# Template register map
Vendor: VendorName Co.Ltd; Series: SeriesName; File version: 1.2
CPU: CM7 r0p1, little endian, MPU, FPU, 4 interrupt priority bits
Registers are 32-bit, read-write, no defined reset value unless marked. A register's access mark holds for its fields unless they carry their own. Offsets are from the block's base; [hi:lo] are bit positions; {n}, {i} and the like mark numbered series.

## TRNG — True Random Number Generator
Base 0x40082000
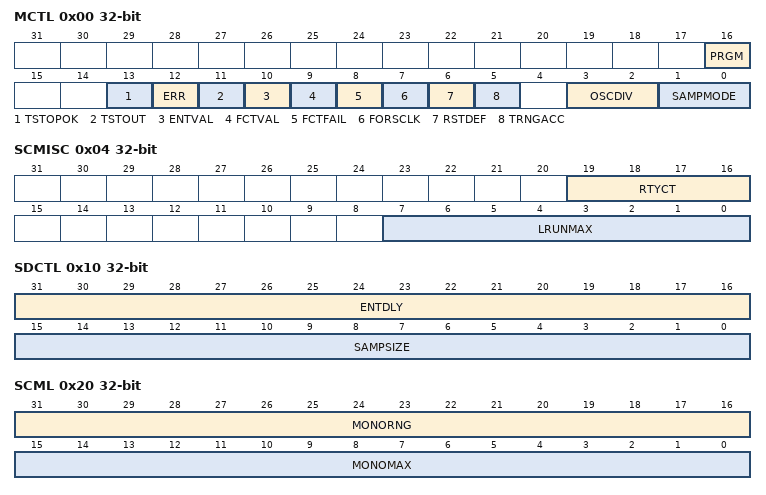
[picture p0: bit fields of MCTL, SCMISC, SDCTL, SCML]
0x00 MCTL — TRNG miscellaneous control register
  [16] PRGM — TRNG PRGM bit: programming mode select
  [13] TSTOPOK ro — TRNG TSTOPOK bit: TRNG module status
  [12] ERR — TRNG ERR bit: error status
  [11] TSTOUT ro — TRNG TSTOUT bit: test points within the ring oscillator
  [10] ENTVAL ro — TRNG ENTVAL bit: whether random number valid
  [9] FCTVAL ro — TRNG FCTVAL bit: whether frequency counting valid
  [8] FCTFAIL ro — TRNG FCTFAIL bit: counting frequency is normal or failure
  [7] FORSCLK — TRNG FORSCLK bit: force system clock
  [6] RSTDEF wo — TRNG RSTDEF bit: reset default
  [5] TRNGACC — TRNG TRNGACC bit: TRNG access mode
  [3:2] OSCDIV — TRNG OSCDIV[1:0] bit: oscillator divide
  [1:0] SAMPMODE — TRNG SAMPMODE[1:0] bit: sample mode
0x04 SCMISC — TRNG statistical check miscellaneous register
  [19:16] RTYCT — TRNG RTYCT[3:0] bit: retry count
  [7:0] LRUNMAX — TRNG LRUNMAX[7:0] bit: long run max limit
0x08 PKRRNG — TRNG poker range register
  [15:0] PKRRNG — TRNG PKRRNG[15:0] bit: poker range
0x0C PKRMAX — TRNG poker maximum limit register
  [23:0] PKRMAX — TRNG PKRMAX[23:0] bit: poker maximum limit
0x0C PKRSQ ro (alternate view of PKRMAX) — TRNG poker square calculation result register
  [23:0] PKRSQ — TRNG PKRSQ[23:0] bit: poker square calculation result
0x10 SDCTL — TRNG poker square calculation result register
  [31:16] ENTDLY — TRNG ENTDLY[15:0] bit: entropy delay
  [15:0] SAMPSIZE — TRNG SAMPSIZE[15:0] bit: sample size
0x14 SBLIM — TRNG sparse bit limit register
  [9:0] SBLIM — TRNG SBLIM[9:0] bit: sparse bit limit
0x14 TOTSAM ro (alternate view of SBLIM) — TRNG total samples register
  [19:0] TOTSAM — TRNG TOTSAM[19:0] bit: total sample
0x18 FRQMIN — TRNG frequency count minimum limit register
  [21:0] FRQMIN — TRNG FRQMIN[21:0] bit: frequency count minimum limit
0x1C FRQCNT ro — TRNG frequency count register
  [21:0] FRQCT — TRNG FRQCT[21:0] bit: frequency count
0x1C FRQMAX (alternate view of FRQCNT) — TRNG frequency count maximum limit register
  [21:0] FRQMAX — TRNG FRQMAX[21:0] bit: frequency counter maximum limit
0x20 SCMC ro — TRNG statistical check monobit count register
  [15:0] MONOCT — TRNG MONOCT[15:0] bit: monobit count
0x20 SCML (alternate view of SCMC) — TRNG statistical check monobit limit register
  [31:16] MONORNG — TRNG MONORNG[15:0] bit: monobit count
  [15:0] MONOMAX — TRNG MONOMAX[15:0] bit: monobit maximum limit
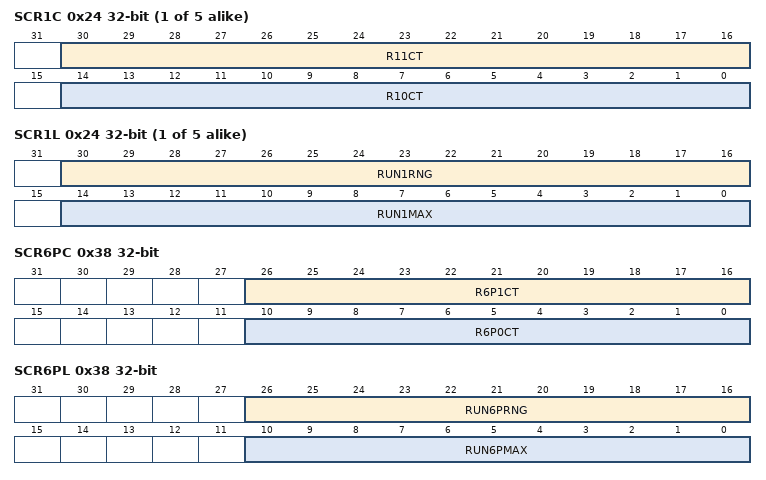
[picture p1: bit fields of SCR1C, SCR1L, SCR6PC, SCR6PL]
{0x20+4i} SCR{i}C ro (i=1..5) — TRNG statistical check run length {i} count register
  [{31-i}:16] R{10i+1}CT — TRNG R{10i+1}CT[{15-i}:0] bit: runs of one length {i} count
  [{15-i}:0] R{10i}CT — TRNG R{10i}CT[{15-i}:0] bit: runs of zero length {i} count
{0x20+4i} SCR{i}L (alternate view of SCR{i}C) (i=1..5) — TRNG statistical check run length {i} limit register
  [{31-i}:16] RUN{i}RNG — TRNG RUN{i}RNG[{15-i}:0] bit: run length {i} range
  [{15-i}:0] RUN{i}MAX — TRNG RUN{i}MAX[{15-i}:0] bit: run length {i} maximum limit
0x38 SCR6PC ro — TRNG statistical check run length 6 count register
  [26:16] R6P1CT — TRNG R6P1CT[10:0] bit: runs of one length 6 count
  [10:0] R6P0CT — TRNG R6P0CT[10:0] bit: runs of zero length 6 count
0x38 SCR6PL (alternate view of SCR6PC) — TRNG statistical check run length 6 limit register
  [26:16] RUN6PRNG — TRNG RUN6PRNG[10:0] bit: run length 6 range
  [10:0] RUN6PMAX — TRNG RUN6PMAX[10:0] bit: run length 6 maximum limit
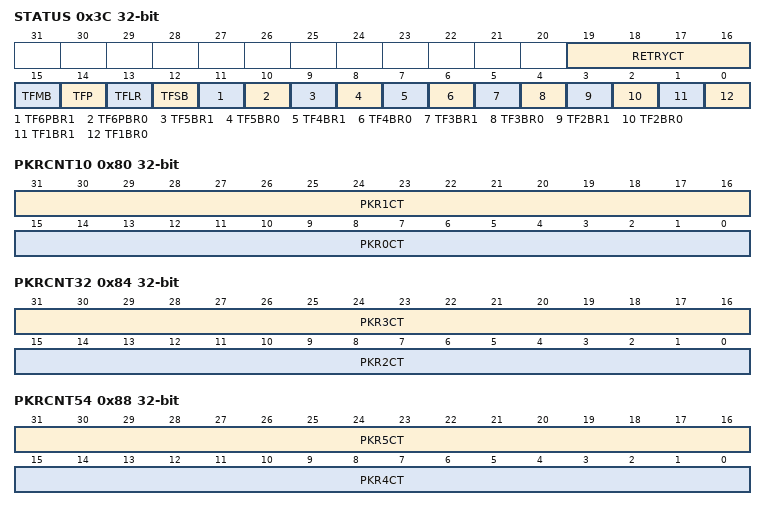
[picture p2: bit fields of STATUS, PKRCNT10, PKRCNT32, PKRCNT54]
0x3C STATUS ro — TRNG status register
  [19:16] RETRYCT — TRNG RETRYCT[3:0] bit: retry count
  [15] TFMB — TRNG TFMB bit: single bit testing result
  [14] TFP — TRNG TFP bit: poker testing result
  [13] TFLR — TRNG TFLR bit: long sequence testing result
  [12] TFSB — TRNG TFSB bit: sparse bits testing result
  [11] TF6PBR1 — TRNG TF6PBR1 bit: more than six consecutive ones testing result
  [10] TF6PBR0 — TRNG TF6PBR0 bit: more than six consecutive zeros testing result
  [9] TF5BR1 — TRNG TF5BR1 bit: five consecutive ones testing result
  [8] TF5BR0 — TRNG TF5BR0 bit: five consecutive zeros testing result
  [7] TF4BR1 — TRNG TF4BR1 bit: four consecutive ones testing result
  [6] TF4BR0 — TRNG TF4BR0 bit: four consecutive zeros testing result
  [5] TF3BR1 — TRNG TF3BR1 bit: three consecutive ones testing result
  [4] TF3BR0 — TRNG TF3BR0 bit: three consecutive zeros testing result
  [3] TF2BR1 — TRNG TF2BR1 bit: two consecutive ones testing result
  [2] TF2BR0 — TRNG TF2BR0 bit: two consecutive zeros testing result
  [1] TF1BR1 — TRNG TF1BR1 bit: one consecutive one testing result
  [0] TF1BR0 — TRNG TF1BR0 bit: one consecutive zero testing result
{0x40+4i} ENTX[{i}] (i=0..15) ro — Grouping of ENT0~ENT15
  [31:0] ENT — TRNG ENT[31:0] bit: entropy value
0x80 PKRCNT10 ro — TRNG statistical check poker count 1 and 0 register
  [31:16] PKR1CT — TRNG PKR1CT[15:0] bit: poker 1h count
  [15:0] PKR0CT — TRNG PKR0CT[15:0] bit: poker 0h count
0x84 PKRCNT32 ro — TRNG statistical check poker count 3 and 2 register
  [31:16] PKR3CT — TRNG PKR3CT[15:0] bit: poker 3h count
  [15:0] PKR2CT — TRNG PKR2CT[15:0] bit: poker 2h count
0x88 PKRCNT54 ro — TRNG statistical check poker count 5 and 4 register
  [31:16] PKR5CT — TRNG PKR5CT[15:0] bit: poker 5h count
  [15:0] PKR4CT — TRNG PKR4CT[15:0] bit: poker 4h count
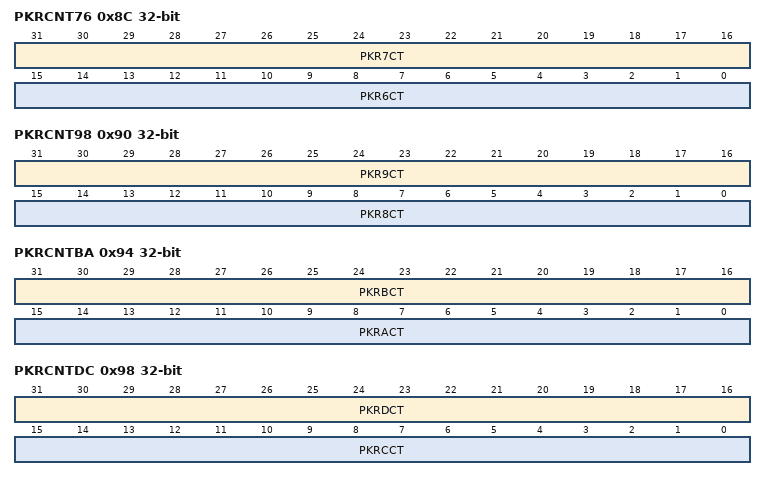
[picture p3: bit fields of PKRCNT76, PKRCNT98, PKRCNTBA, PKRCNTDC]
0x8C PKRCNT76 ro — TRNG statistical check poker count 7 and 6 register
  [31:16] PKR7CT — TRNG PKR7CT[15:0] bit: poker 7h count
  [15:0] PKR6CT — TRNG PKR6CT[15:0] bit: poker 6h count
0x90 PKRCNT98 ro — TRNG statistical check poker count 9 and 8 register
  [31:16] PKR9CT — TRNG PKR9CT[15:0] bit: poker 9h count
  [15:0] PKR8CT — TRNG PKR8CT[15:0] bit: poker 8h count
0x94 PKRCNTBA ro — TRNG statistical check poker count B and A register
  [31:16] PKRBCT — TRNG PKRBCT[15:0] bit: poker Bh count
  [15:0] PKRACT — TRNG PKRACT[15:0] bit: poker Ah count
0x98 PKRCNTDC ro — TRNG statistical check poker count D and C register
  [31:16] PKRDCT — TRNG PKRDCT[15:0] bit: poker Dh count
  [15:0] PKRCCT — TRNG PKRCCT[15:0] bit: poker Ch count
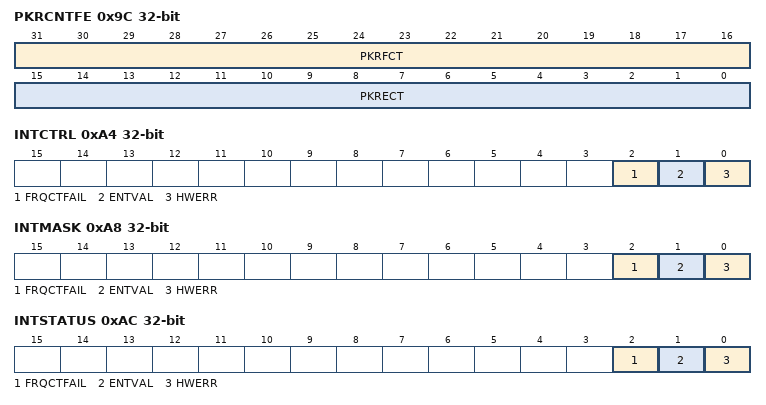
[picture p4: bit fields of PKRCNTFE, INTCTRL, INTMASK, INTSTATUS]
0x9C PKRCNTFE ro — TRNG statistical check poker count F and E register
  [31:16] PKRFCT — TRNG PKRFCT[15:0] bit: poker Fh count
  [15:0] PKRECT — TRNG PKRECT[15:0] bit: poker Eh count
0xA0 SECCFG — TRNG security configuration register
  [1] NOPRGM — TRNG NOPRGM bit: whether the TRNG registers can be programmed
0xA4 INTCTRL — TRNG interrupt control register
  [2] FRQCTFAIL — TRNG FRQCTFAIL bit: FRQCTFAIL interruption enable
  [1] ENTVAL — TRNG ENTVAL bit: ENTVAL interruption enable
  [0] HWERR — TRNG HWERR bit: HWERR interruption enable
0xA8 INTMASK — TRNG mask register
  [2] FRQCTFAIL — TRNG FRQCTFAIL bit: FRQCTFAIL will be shielded or activated
  [1] ENTVAL — TRNG ENTVAL bit: ENTVAL will be shielded or activated
  [0] HWERR — TRNG HWERR bit: HWERR will be shielded or activated
0xAC INTSTATUS ro — TRNG interrupt status register
  [2] FRQCTFAIL — TRNG FRQCTFAIL bit: frequency count fail
  [1] ENTVAL — TRNG ENTVAL bit: entropy valid
  [0] HWERR — TRNG HWERR bit: error status
